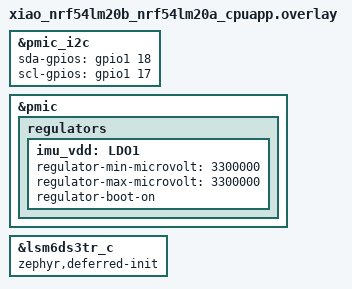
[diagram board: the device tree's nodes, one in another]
&pmic_i2c {
	sda-gpios = <&gpio1 18 GPIO_ACTIVE_HIGH>;
	scl-gpios = <&gpio1 17 GPIO_ACTIVE_HIGH>;
	status = "okay";
};

&pmic {
	regulators {
		imu_vdd: LDO1 {
			regulator-min-microvolt = <3300000>;
			regulator-max-microvolt = <3300000>;
			regulator-boot-on;
		};
	};
};

&lsm6ds3tr_c {
	zephyr,deferred-init;
};
